# target register map
Vendor: Vango; Series: TARGET; File version: 1.0
CPU: CM0 r0p0, little endian, no MPU, no FPU, 2 interrupt priority bits
Registers are 32-bit, read-write, reset 0x0 unless marked. A register's access mark holds for its fields unless they carry their own. Offsets are from the block's base; [hi:lo] are bit positions; {n}, {i} and the like mark numbered series.

## LCD — The LCD controller is used to display content on the LCD panel.
Base 0x40002000
{0x0+4i} FB[{i}] (i=0..39) reset not defined — LCD Frame buffer x register
  [31:0] DATA — Each bit represents a data in the display array.
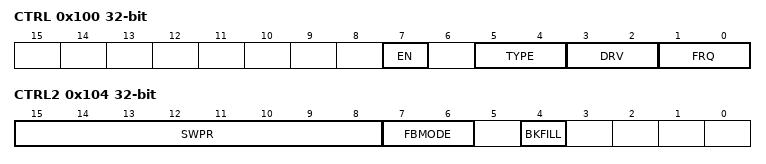
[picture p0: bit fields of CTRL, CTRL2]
0x100 CTRL — LCD control register.
  [7] EN — LCD controller enable register.
  [5:4] TYPE — LCD type control register.
    0=4_COM; 1=6_COM; 2=8_COM
  [3:2] DRV — LCD driving resister control register.
    0=300kohm; 1=600kohm; 2=150kohm; 3=200kohm
  [1:0] FRQ — LCD scan frequency.
    0=64Hz; 1=128HZ; 2=256HZ; 3=512HZ
0x104 CTRL2 — LCD control register2.
  [15:8] SWPR — Frame buffer switch period.
  [7:6] FBMODE — LCD frame buffer switch mode control register.
    0=BufferA; 1=BufferA_and_BufferB; 2=BufferA_and_Blank
  [4] BKFILL — Fill value at blank period.
0x108 SEGCTRL0 — LCD segment enable control register 0
  [31:0] SEGCTRL — Each bit control the SEG0~SEG31 LCD signal enable.
0x10C SEGCTRL1 — LCD segment enable control register 1
  [31:0] SEGCTRL — Each bit control the SEG32~SEG63 LCD signal enable.
0x110 SEGCTRL2 — LCD segment enable control register 2
  [15:0] SEGCTRL — Each bit control the SEG64~SEG79 LCD signal enable.

## MISC1 — The MISC controller is used to control some special function of TARGET, which will be power-off during sleep and deep-sleep mode.
Base 0x40013000
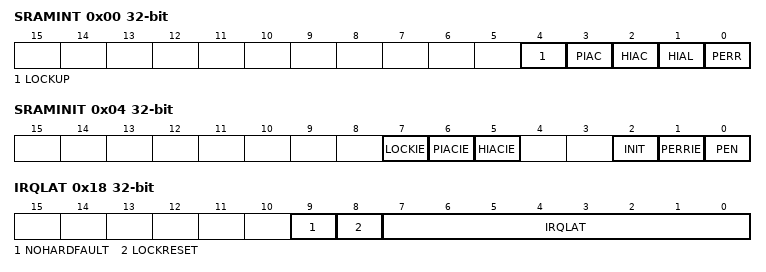
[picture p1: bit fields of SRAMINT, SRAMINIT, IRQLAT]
0x00 SRAMINT — SRAM Parity Error Interrupt.
  [4] LOCKUP write-1-clears — This bit indicates the CM0 lockup has happened.
  [3] PIAC write-1-clears — This bit indicates that an invalid address access on APB bus is occurred.
  [2] HIAC write-1-clears — This bit indicates that an invalid address access on AHB bus is occurred.
  [1] HIAL write-1-clears — This bit indicates that an invalid align access on AHB bus is occurred.
  [0] PERR write-1-clears — This bit indicates that a SRAM parity error is happened during the SRAM read process.
0x04 SRAMINIT — SRAM initialize register.
  [7] LOCKIE — CM0 lockup NMI enable register.
  [6] PIACIE — APB invalid address access NMI enable register.
  [5] HIACIE — AHB invalid address access NMI enable register.
  [2] INIT — SRAM initialize register.
  [1] PERRIE — SRAM parity error NMI enable register.
  [0] PEN — Parity check enable register.
0x08 PARERR ro — SRAM Parity Error address register.
  [13:0] PEADDR — Parity error address.
0x0C IREN — IR enable control register.
  [5:0] IREN
0x10 DUTYL — IR Duty low pulse control register.
  [15:0] DUTYL — IR low pulse width control register.
0x14 DUTYH — IR Duty high pulse control register.
  [15:0] DUTYH — IR high pulse width control register.
0x18 IRQLAT — Cortex M0 IRQ latency control register.
  [9] NOHARDFAULT — This register is used to disable the hard fault generation to CPU.
  [8] LOCKRESET — This register is used to control if the lockup will issue a system reset.
  [7:0] IRQLAT — This register is used to control the Cortex M0 IRQ latency.
0x20 HIADDR ro — AHB invalid access address.
0x24 PIADDR ro — APB invalid access address.

## MISC2 — MISC2 controller is in retention domain which will be power-off at deep-sleep mode.
Base 0x40013E00
0x00 FLASHWC — Flash wait cycle register.
  [13:8] CYCLE_1US — This register is used for Flash controller to calculate 1us tick from AHB clock 1us tick = (AHB clock period)*(CYCLE_1US+1)
0x04 CLKSEL — Clock selection register.
  [2:0] CLKSEL — This register is used to control AHB clock source.
    0=RCH; 1=XOH; 2=PLLH; 3=RTCCLK (controlled by RTCLK_SEL in PMU_CONTROL register); 4=PLLL
0x08 CLKDIVH — AHB clock divider control register.
  [7:0] CLKDIVH — This register is used to control AHB clock divider.
0x0C CLKDIVP reset 0x1 — APB clock divider control register.
  [7:0] CLKDIVP — This register is used to control APB clock divider.
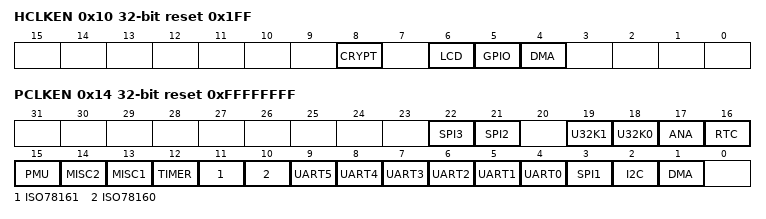
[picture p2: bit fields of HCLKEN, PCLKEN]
0x10 HCLKEN reset 0x1FF — AHB clock enable control register.
  [8] CRYPT — CRYPT Controller.
  [6] LCD — LCD Controller.
  [5] GPIO — GPIO Controller.
  [4] DMA — DMA Controller.
0x14 PCLKEN reset 0xFFFFFFFF — APB clock enable control register.
  [22] SPI3 — SPI3 Controller.
  [21] SPI2 — SPI2 Controller.
  [19] U32K1 — U32K1 Controller.
  [18] U32K0 — U32K0 Controller.
  [17] ANA — ANA Controller.
  [16] RTC — RTC Controller.
  [15] PMU — PMU Controller.
  [14] MISC2 — MISC2 Controller.
  [13] MISC1 — MISC1 Controller.
  [12] TIMER — Timer Controller.
  [11] ISO78161 — ISO78161 Controller.
  [10] ISO78160 — ISO78160 Controller.
  [n+4] UART{n} (n=0..5) — UART{n} Controller.
  [3] SPI1 — SPI1 Controller.
  [2] I2C — I2C Controller.
  [1] DMA — DMA Controller.
